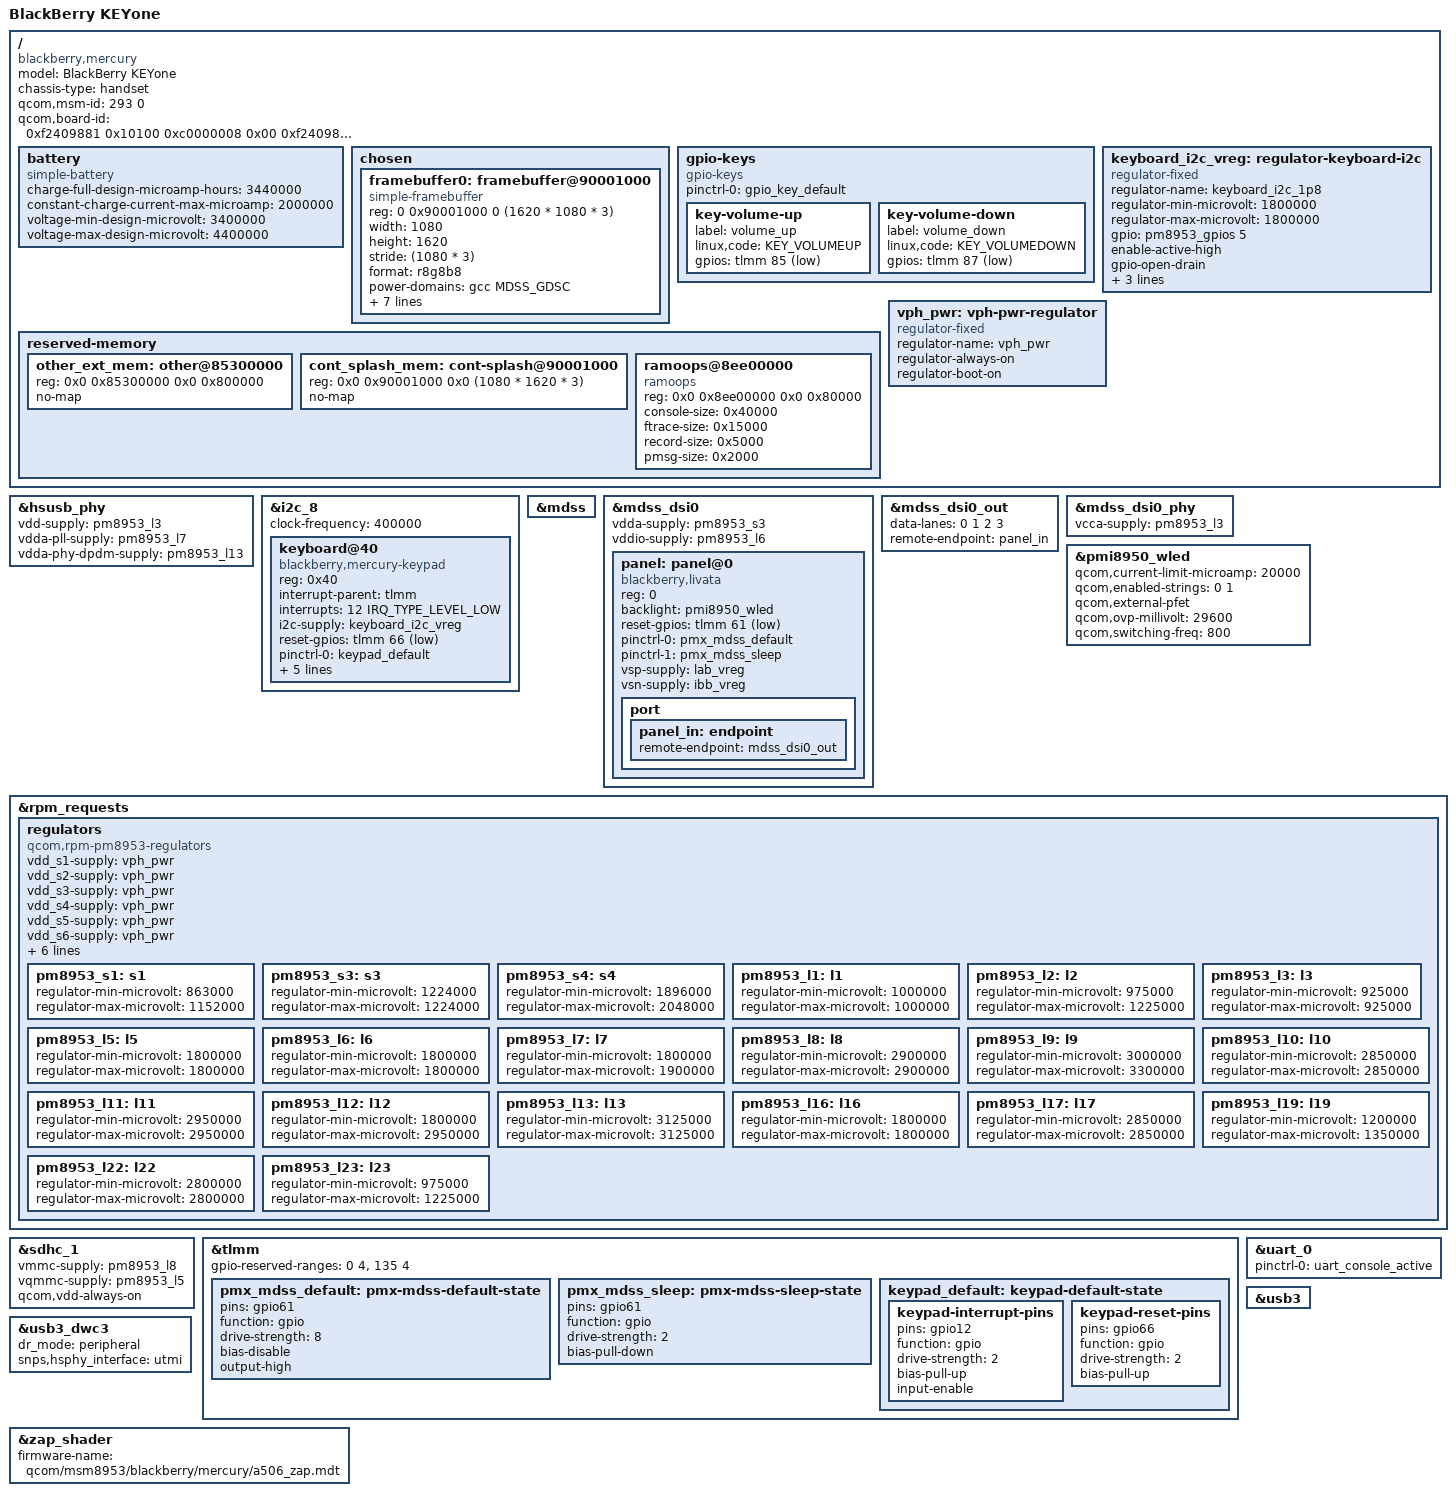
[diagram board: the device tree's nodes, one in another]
// SPDX-License-Identifier: GPL-2.0-only
/dts-v1/;

#include "msm8953.dtsi"
#include "pm8953.dtsi"
#include "pmi8950.dtsi"

#include <dt-bindings/gpio/gpio.h>
#include <dt-bindings/input/input.h>
#include <dt-bindings/interrupt-controller/irq.h>

/delete-node/ &cont_splash_mem;

/ {
	model = "BlackBerry KEYone";
	compatible = "blackberry,mercury", "qcom,msm8953";
	chassis-type = "handset";
	qcom,msm-id = <293 0>;
	qcom,board-id = <0xf2409881 0x10100 0xc0000008 0x00
			 0xf24098b2 0x10100 0xc1000008 0x00
			 0xf24098b1 0x10100 0xc2000008 0x00
			 0xf2409870 0x10100 0xc3000008 0x00
			 0xc6000008 0x00 0xc7000008 0x00
			 0xc8000008 0x00 0x2000b 0x00 0x08 0x00
			 0xf240987e 0x10100 0xf2409867 0x10100>;

	battery: battery {
		compatible = "simple-battery";
		charge-full-design-microamp-hours = <3440000>;
		constant-charge-current-max-microamp = <2000000>;
		voltage-min-design-microvolt = <3400000>;
		voltage-max-design-microvolt = <4400000>;
	};

	chosen {
		#address-cells = <2>;
		#size-cells = <2>;
		ranges;

		framebuffer0: framebuffer@90001000 {
			compatible = "simple-framebuffer";
			reg = <0 0x90001000 0 (1620 * 1080 * 3)>;

			width = <1080>;
			height = <1620>;
			stride = <(1080 * 3)>;
			format = "r8g8b8";

			power-domains = <&gcc MDSS_GDSC>;

			clocks = <&gcc GCC_MDSS_AHB_CLK>,
				 <&gcc GCC_MDSS_AXI_CLK>,
				 <&gcc GCC_MDSS_VSYNC_CLK>,
				 <&gcc GCC_MDSS_MDP_CLK>,
				 <&gcc GCC_MDSS_BYTE0_CLK>,
				 <&gcc GCC_MDSS_PCLK0_CLK>,
				 <&gcc GCC_MDSS_ESC0_CLK>;
		};
	};

	gpio-keys {
		compatible = "gpio-keys";

		pinctrl-names = "default";
		pinctrl-0 = <&gpio_key_default>;

		key-volume-up {
			label = "volume_up";
			linux,code = <KEY_VOLUMEUP>;
			gpios = <&tlmm 85 GPIO_ACTIVE_LOW>;
		};

		key-volume-down {
			label = "volume_down";
			linux,code = <KEY_VOLUMEDOWN>;
			gpios = <&tlmm 87 GPIO_ACTIVE_LOW>;
		};
	};

	reserved-memory {
		other_ext_mem: other@85300000 {
			reg = <0x0 0x85300000 0x0 0x800000>;
			no-map;
		};

		cont_splash_mem: cont-splash@90001000 {
			reg = <0x0 0x90001000 0x0 (1080 * 1620 * 3)>;
			no-map;
		};

		ramoops@8ee00000 {
			compatible = "ramoops";
			reg = <0x0 0x8ee00000 0x0 0x80000>;
			console-size = <0x40000>;
			ftrace-size = <0x15000>;
			record-size = <0x5000>;
			pmsg-size = <0x2000>;
		};
	};

	keyboard_i2c_vreg: regulator-keyboard-i2c {
		compatible = "regulator-fixed";
		regulator-name = "keyboard_i2c_1p8";
		regulator-min-microvolt = <1800000>;
		regulator-max-microvolt = <1800000>;

		gpio = <&pm8953_gpios 5 GPIO_ACTIVE_HIGH>;
		enable-active-high;
		gpio-open-drain;

		regulator-always-on;
		regulator-boot-on;
		vin-supply = <&pm8953_l6>;
	};

	vph_pwr: vph-pwr-regulator {
		compatible = "regulator-fixed";
		regulator-name = "vph_pwr";
		regulator-always-on;
		regulator-boot-on;
	};

};

&hsusb_phy {
	vdd-supply = <&pm8953_l3>;
	vdda-pll-supply = <&pm8953_l7>;
	vdda-phy-dpdm-supply = <&pm8953_l13>;

	status = "okay";
};

&i2c_8 {
	clock-frequency = <400000>;

	status = "okay";

	keyboard@40 {
		compatible = "blackberry,mercury-keypad";
		reg = <0x40>;

		interrupt-parent = <&tlmm>;
		interrupts = <12 IRQ_TYPE_LEVEL_LOW>;
		i2c-supply = <&keyboard_i2c_vreg>;
		reset-gpios = <&tlmm 66
				 (GPIO_ACTIVE_LOW | GPIO_OPEN_DRAIN)>;

		pinctrl-names = "default";
		pinctrl-0 = <&keypad_default>;

		keypad,num-rows = <8>;
		keypad,num-columns = <8>;
		linux,keymap = <MATRIX_KEY(3, 1, KEY_Q)
				   MATRIX_KEY(3, 7, KEY_W)
				   MATRIX_KEY(4, 1, KEY_E)
				   MATRIX_KEY(5, 1, KEY_R)
				   MATRIX_KEY(5, 4, KEY_T)
				   MATRIX_KEY(6, 4, KEY_Y)
				   MATRIX_KEY(6, 1, KEY_U)
				   MATRIX_KEY(7, 4, KEY_I)
				   MATRIX_KEY(7, 1, KEY_O)
				   MATRIX_KEY(4, 2, KEY_P)
				   MATRIX_KEY(3, 4, KEY_A)
				   MATRIX_KEY(4, 7, KEY_S)
				   MATRIX_KEY(4, 4, KEY_D)
				   MATRIX_KEY(5, 5, KEY_F)
				   MATRIX_KEY(5, 7, KEY_G)
				   MATRIX_KEY(6, 7, KEY_H)
				   MATRIX_KEY(6, 5, KEY_J)
				   MATRIX_KEY(7, 5, KEY_K)
				   MATRIX_KEY(7, 7, KEY_L)
				   MATRIX_KEY(7, 2, KEY_BACKSPACE)
				   MATRIX_KEY(3, 6, KEY_LEFTALT)
				   MATRIX_KEY(4, 0, KEY_Z)
				   MATRIX_KEY(4, 6, KEY_X)
				   MATRIX_KEY(5, 0, KEY_C)
				   MATRIX_KEY(5, 6, KEY_V)
				   MATRIX_KEY(6, 6, KEY_B)
				   MATRIX_KEY(6, 0, KEY_N)
				   MATRIX_KEY(7, 0, KEY_M)
				   MATRIX_KEY(7, 6, KEY_4)
				   MATRIX_KEY(6, 2, KEY_ENTER)
				   MATRIX_KEY(4, 5, KEY_LEFTSHIFT)
				   MATRIX_KEY(3, 5, KEY_0)
				   MATRIX_KEY(3, 0, KEY_SPACE)
				   MATRIX_KEY(3, 2, KEY_RIGHTALT)
				   MATRIX_KEY(5, 2, KEY_RIGHTSHIFT)>;
		wakeup-source;
	};
};

&mdss {
	status = "okay";
};

&mdss_dsi0 {
	vdda-supply = <&pm8953_s3>;
	vddio-supply = <&pm8953_l6>;

	status = "okay";

	panel: panel@0 {
		compatible = "blackberry,livata";
		reg = <0>;

		backlight = <&pmi8950_wled>;

		reset-gpios = <&tlmm 61 GPIO_ACTIVE_LOW>;

		pinctrl-names = "default", "sleep";
		pinctrl-0 = <&pmx_mdss_default>;
		pinctrl-1 = <&pmx_mdss_sleep>;

		vsp-supply = <&lab_vreg>;
		vsn-supply = <&ibb_vreg>;

		port {
			panel_in: endpoint {
				remote-endpoint = <&mdss_dsi0_out>;
			};
		};
	};
};

&mdss_dsi0_out {
	data-lanes = <0 1 2 3>;
	remote-endpoint = <&panel_in>;
};

&mdss_dsi0_phy {
	vcca-supply = <&pm8953_l3>;

	status = "okay";
};

&pmi8950_wled {
	qcom,current-limit-microamp = <20000>;
	qcom,enabled-strings = <0 1>;
	qcom,external-pfet;
	qcom,ovp-millivolt = <29600>;
	qcom,switching-freq = <800>;

	status = "okay";
};

&rpm_requests {
	regulators {
		compatible = "qcom,rpm-pm8953-regulators";
		vdd_s1-supply = <&vph_pwr>;
		vdd_s2-supply = <&vph_pwr>;
		vdd_s3-supply = <&vph_pwr>;
		vdd_s4-supply = <&vph_pwr>;
		vdd_s5-supply = <&vph_pwr>;
		vdd_s6-supply = <&vph_pwr>;
		vdd_s7-supply = <&vph_pwr>;
		vdd_l1-supply = <&pm8953_s3>;
		vdd_l2_l3-supply = <&pm8953_s3>;
		vdd_l4_l5_l6_l7_l16_l19-supply = <&pm8953_s4>;
		vdd_l8_l11_l12_l13_l14_l15-supply = <&vph_pwr>;
		vdd_l9_l10_l17_l18_l22-supply = <&vph_pwr>;

		pm8953_s1: s1 {
			regulator-min-microvolt = <863000>;
			regulator-max-microvolt = <1152000>;
		};

		pm8953_s3: s3 {
			regulator-min-microvolt = <1224000>;
			regulator-max-microvolt = <1224000>;
		};

		pm8953_s4: s4 {
			regulator-min-microvolt = <1896000>;
			regulator-max-microvolt = <2048000>;
		};

		pm8953_l1: l1 {
			regulator-min-microvolt = <1000000>;
			regulator-max-microvolt = <1000000>;
		};

		pm8953_l2: l2 {
			regulator-min-microvolt = <975000>;
			regulator-max-microvolt = <1225000>;
		};

		pm8953_l3: l3 {
			regulator-min-microvolt = <925000>;
			regulator-max-microvolt = <925000>;
		};

		pm8953_l5: l5 {
			regulator-min-microvolt = <1800000>;
			regulator-max-microvolt = <1800000>;
		};

		pm8953_l6: l6 {
			regulator-min-microvolt = <1800000>;
			regulator-max-microvolt = <1800000>;
		};

		pm8953_l7: l7 {
			regulator-min-microvolt = <1800000>;
			regulator-max-microvolt = <1900000>;
		};

		pm8953_l8: l8 {
			regulator-min-microvolt = <2900000>;
			regulator-max-microvolt = <2900000>;
		};

		pm8953_l9: l9 {
			regulator-min-microvolt = <3000000>;
			regulator-max-microvolt = <3300000>;
		};

		pm8953_l10: l10 {
			regulator-min-microvolt = <2850000>;
			regulator-max-microvolt = <2850000>;
		};

		pm8953_l11: l11 {
			regulator-min-microvolt = <2950000>;
			regulator-max-microvolt = <2950000>;
		};

		pm8953_l12: l12 {
			regulator-min-microvolt = <1800000>;
			regulator-max-microvolt = <2950000>;
		};

		pm8953_l13: l13 {
			regulator-min-microvolt = <3125000>;
			regulator-max-microvolt = <3125000>;
		};

		pm8953_l16: l16 {
			regulator-min-microvolt = <1800000>;
			regulator-max-microvolt = <1800000>;
		};

		pm8953_l17: l17 {
			regulator-min-microvolt = <2850000>;
			regulator-max-microvolt = <2850000>;
		};

		pm8953_l19: l19 {
			regulator-min-microvolt = <1200000>;
			regulator-max-microvolt = <1350000>;
		};

		pm8953_l22: l22 {
			regulator-min-microvolt = <2800000>;
			regulator-max-microvolt = <2800000>;
		};

		pm8953_l23: l23 {
			regulator-min-microvolt = <975000>;
			regulator-max-microvolt = <1225000>;
		};
	};
};

&sdhc_1 {
	vmmc-supply = <&pm8953_l8>;
	vqmmc-supply = <&pm8953_l5>;
	qcom,vdd-always-on;

	status = "okay";
};

&tlmm {
	gpio-reserved-ranges = <0 4>, <135 4>;

	pmx_mdss_default: pmx-mdss-default-state {
		pins = "gpio61";
		function = "gpio";
		drive-strength = <8>;
		bias-disable;
		output-high;
	};

	pmx_mdss_sleep: pmx-mdss-sleep-state {
		pins = "gpio61";
		function = "gpio";
		drive-strength = <2>;
		bias-pull-down;
	};

	keypad_default: keypad-default-state {
		keypad-interrupt-pins {
			pins = "gpio12";
			function = "gpio";
			drive-strength = <2>;
			bias-pull-up;
			input-enable;
		};

		keypad-reset-pins {
			pins = "gpio66";
			function = "gpio";
			drive-strength = <2>;
			bias-pull-up;
		};
	};
};

&uart_0 {
	pinctrl-0 = <&uart_console_active>;
	pinctrl-names = "default";

	status = "okay";
};

&usb3 {
	status = "okay";
};

&usb3_dwc3 {
	dr_mode = "peripheral";
	snps,hsphy_interface = "utmi";
};

&zap_shader {
	firmware-name = "qcom/msm8953/blackberry/mercury/a506_zap.mdt";
};
